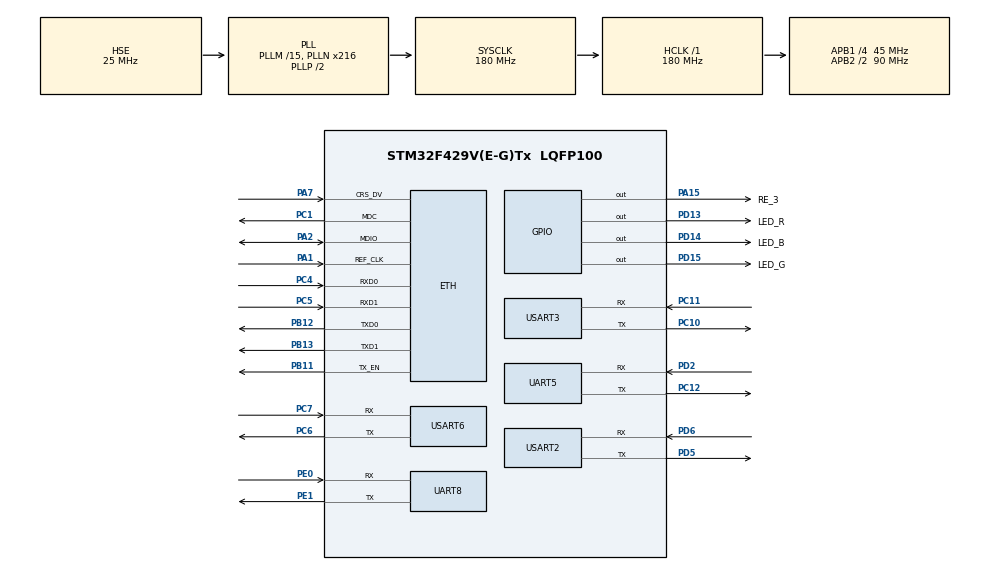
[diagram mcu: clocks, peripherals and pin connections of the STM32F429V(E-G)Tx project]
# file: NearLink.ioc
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ETH.MediaInterface=HAL_ETH_RMII_MODE
Mcu.Family=STM32F4
Mcu.Name=STM32F429V(E-G)Tx
Mcu.Package=LQFP100
NVIC.PriorityGroup=NVIC_PRIORITYGROUP_4
PA1.Mode=RMII
PA1.Signal=ETH_REF_CLK
PA13.Mode=Serial_Wire
PA13.Signal=SYS_JTMS-SWDIO
PA14.Mode=Serial_Wire
PA14.Signal=SYS_JTCK-SWCLK
PA15.GPIO_Label=RE_3
PA15.Signal=GPIO_Output
PA2.Mode=RMII
PA2.Signal=ETH_MDIO
PA7.Mode=RMII
PA7.Signal=ETH_CRS_DV
PB11.Mode=RMII
PB11.Signal=ETH_TX_EN
PB12.Mode=RMII
PB12.Signal=ETH_TXD0
PB13.Mode=RMII
PB13.Signal=ETH_TXD1
PC1.Mode=RMII
PC1.Signal=ETH_MDC
PC10.Mode=Asynchronous
PC10.Signal=USART3_TX
PC11.Mode=Asynchronous
PC11.Signal=USART3_RX
PC12.Mode=Asynchronous
PC12.Signal=UART5_TX
PC4.Mode=RMII
PC4.Signal=ETH_RXD0
PC5.Mode=RMII
PC5.Signal=ETH_RXD1
PC6.Mode=Asynchronous
PC6.Signal=USART6_TX
PC7.Mode=Asynchronous
PC7.Signal=USART6_RX
PD13.GPIO_Label=LED_R
PD13.PinState=GPIO_PIN_SET
PD13.Signal=GPIO_Output
PD14.GPIO_Label=LED_B
PD14.PinState=GPIO_PIN_SET
PD14.Signal=GPIO_Output
PD15.GPIO_Label=LED_G
PD15.PinState=GPIO_PIN_SET
PD15.Signal=GPIO_Output
PD2.Mode=Asynchronous
PD2.Signal=UART5_RX
PD5.Mode=Asynchronous
PD5.Signal=USART2_TX
PD6.Mode=Asynchronous
PD6.Signal=USART2_RX
PE0.Mode=Asynchronous
PE0.Signal=UART8_RX
PE1.Mode=Asynchronous
PE1.Signal=UART8_TX
PH0/OSC_IN.Mode=HSE-External-Oscillator
PH0/OSC_IN.Signal=RCC_OSC_IN
PH1/OSC_OUT.Mode=HSE-External-Oscillator
PH1/OSC_OUT.Signal=RCC_OSC_OUT
ProjectManager.HeapSize=0x200
ProjectManager.StackSize=0x400
ProjectManager.TargetToolchain=MDK-ARM V5.32
RCC.48MHZClocksFreq_Value=90000000
RCC.AHBFreq_Value=180000000
RCC.APB1CLKDivider=RCC_HCLK_DIV4
RCC.APB1Freq_Value=45000000
RCC.APB1TimFreq_Value=90000000
RCC.APB2CLKDivider=RCC_HCLK_DIV2
RCC.APB2Freq_Value=90000000
RCC.APB2TimFreq_Value=180000000
RCC.CortexFreq_Value=180000000
RCC.HCLKFreq_Value=180000000
RCC.HSE_VALUE=25000000
RCC.HSI_VALUE=16000000
RCC.LSE_VALUE=32768
RCC.PLLM=15
RCC.PLLN=216
RCC.PLLSourceVirtual=RCC_PLLSOURCE_HSE
RCC.SYSCLKFreq_VALUE=180000000
RCC.SYSCLKSource=RCC_SYSCLKSOURCE_PLLCLK
RCC.VCOOutputFreq_Value=360000000
UART5.VirtualMode=Asynchronous
UART8.VirtualMode=Asynchronous
USART2.VirtualMode=VM_ASYNC
USART3.VirtualMode=VM_ASYNC
USART6.VirtualMode=VM_ASYNC
board=custom

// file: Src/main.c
/* USER CODE BEGIN Header */
/**
  ******************************************************************************
  * @file           : main.c
  * @brief          : Main program body
  ******************************************************************************
  * @attention
  *
  * Copyright (c) 2024 STMicroelectronics.
  * All rights reserved.
  *
  * This software is licensed under terms that can be found in the LICENSE file
  * in the root directory of this software component.
  * If no LICENSE file comes with this software, it is provided AS-IS.
  *
  ******************************************************************************
  */
/* USER CODE END Header */
#include "main.h"
#include "string.h"

ETH_TxPacketConfig TxConfig;
ETH_DMADescTypeDef  DMARxDscrTab[ETH_RX_DESC_CNT]; /* Ethernet Rx DMA Descriptors */
ETH_DMADescTypeDef  DMATxDscrTab[ETH_TX_DESC_CNT]; /* Ethernet Tx DMA Descriptors */

ETH_HandleTypeDef heth;

UART_HandleTypeDef huart5;
UART_HandleTypeDef huart8;
UART_HandleTypeDef huart2;
UART_HandleTypeDef huart3;
UART_HandleTypeDef huart6;

void SystemClock_Config(void);
static void MX_GPIO_Init(void);
static void MX_ETH_Init(void);
static void MX_UART5_Init(void);
static void MX_UART8_Init(void);
static void MX_USART2_UART_Init(void);
static void MX_USART3_UART_Init(void);
static void MX_USART6_UART_Init(void);

int main(void)
{

  /* MCU Configuration--------------------------------------------------------*/

  /* Reset of all peripherals, Initializes the Flash interface and the Systick. */
  HAL_Init();

  /* Configure the system clock */
  SystemClock_Config();

  /* Initialize all configured peripherals */
  MX_GPIO_Init();
  MX_ETH_Init();
  MX_UART5_Init();
  MX_UART8_Init();
  MX_USART2_UART_Init();
  MX_USART3_UART_Init();
  MX_USART6_UART_Init();
  /* USER CODE BEGIN 2 */
  //LL_SYSTICK_EnableIT();
  /* USER CODE END 2 */

  /* Infinite loop */
  while (1)
  {

  }
}

void SystemClock_Config(void)
{
  RCC_OscInitTypeDef RCC_OscInitStruct = {0};
  RCC_ClkInitTypeDef RCC_ClkInitStruct = {0};

  /** Configure the main internal regulator output voltage
  */
  __HAL_RCC_PWR_CLK_ENABLE();
  __HAL_PWR_VOLTAGESCALING_CONFIG(PWR_REGULATOR_VOLTAGE_SCALE1);

  /** Initializes the RCC Oscillators according to the specified parameters
  * in the RCC_OscInitTypeDef structure.
  */
  RCC_OscInitStruct.OscillatorType = RCC_OSCILLATORTYPE_HSE;
  RCC_OscInitStruct.HSEState = RCC_HSE_ON;
  RCC_OscInitStruct.PLL.PLLState = RCC_PLL_ON;
  RCC_OscInitStruct.PLL.PLLSource = RCC_PLLSOURCE_HSE;
  RCC_OscInitStruct.PLL.PLLM = 15;
  RCC_OscInitStruct.PLL.PLLN = 216;
  RCC_OscInitStruct.PLL.PLLP = RCC_PLLP_DIV2;
  RCC_OscInitStruct.PLL.PLLQ = 4;
  if (HAL_RCC_OscConfig(&RCC_OscInitStruct) != HAL_OK)
  {
    Error_Handler();
  }

  /** Activate the Over-Drive mode
  */
  if (HAL_PWREx_EnableOverDrive() != HAL_OK)
  {
    Error_Handler();
  }

  /** Initializes the CPU, AHB and APB buses clocks
  */
  RCC_ClkInitStruct.ClockType = RCC_CLOCKTYPE_HCLK|RCC_CLOCKTYPE_SYSCLK
                              |RCC_CLOCKTYPE_PCLK1|RCC_CLOCKTYPE_PCLK2;
  RCC_ClkInitStruct.SYSCLKSource = RCC_SYSCLKSOURCE_PLLCLK;
  RCC_ClkInitStruct.AHBCLKDivider = RCC_SYSCLK_DIV1;
  RCC_ClkInitStruct.APB1CLKDivider = RCC_HCLK_DIV4;
  RCC_ClkInitStruct.APB2CLKDivider = RCC_HCLK_DIV2;

  if (HAL_RCC_ClockConfig(&RCC_ClkInitStruct, FLASH_LATENCY_5) != HAL_OK)
  {
    Error_Handler();
  }
}

static void MX_ETH_Init(void)
{

   static uint8_t MACAddr[6];

  heth.Instance = ETH;
  MACAddr[0] = 0x00;
  MACAddr[1] = 0x80;
  MACAddr[2] = 0xE1;
  MACAddr[3] = 0x00;
  MACAddr[4] = 0x00;
  MACAddr[5] = 0x00;
  heth.Init.MACAddr = &MACAddr[0];
  heth.Init.MediaInterface = HAL_ETH_RMII_MODE;
  heth.Init.TxDesc = DMATxDscrTab;
  heth.Init.RxDesc = DMARxDscrTab;
  heth.Init.RxBuffLen = 1524;

  if (HAL_ETH_Init(&heth) != HAL_OK)
  {
    Error_Handler();
  }

  memset(&TxConfig, 0 , sizeof(ETH_TxPacketConfig));
  TxConfig.Attributes = ETH_TX_PACKETS_FEATURES_CSUM | ETH_TX_PACKETS_FEATURES_CRCPAD;
  TxConfig.ChecksumCtrl = ETH_CHECKSUM_IPHDR_PAYLOAD_INSERT_PHDR_CALC;
  TxConfig.CRCPadCtrl = ETH_CRC_PAD_INSERT;

}

static void MX_UART5_Init(void)
{

  huart5.Instance = UART5;
  huart5.Init.BaudRate = 115200;
  huart5.Init.WordLength = UART_WORDLENGTH_8B;
  huart5.Init.StopBits = UART_STOPBITS_1;
  huart5.Init.Parity = UART_PARITY_NONE;
  huart5.Init.Mode = UART_MODE_TX_RX;
  huart5.Init.HwFlowCtl = UART_HWCONTROL_NONE;
  huart5.Init.OverSampling = UART_OVERSAMPLING_16;
  if (HAL_UART_Init(&huart5) != HAL_OK)
  {
    Error_Handler();
  }

}

static void MX_UART8_Init(void)
{

  huart8.Instance = UART8;
  huart8.Init.BaudRate = 115200;
  huart8.Init.WordLength = UART_WORDLENGTH_8B;
  huart8.Init.StopBits = UART_STOPBITS_1;
  huart8.Init.Parity = UART_PARITY_NONE;
  huart8.Init.Mode = UART_MODE_TX_RX;
  huart8.Init.HwFlowCtl = UART_HWCONTROL_NONE;
  huart8.Init.OverSampling = UART_OVERSAMPLING_16;
  if (HAL_UART_Init(&huart8) != HAL_OK)
  {
    Error_Handler();
  }

}

static void MX_USART2_UART_Init(void)
{

  huart2.Instance = USART2;
  huart2.Init.BaudRate = 115200;
  huart2.Init.WordLength = UART_WORDLENGTH_8B;
  huart2.Init.StopBits = UART_STOPBITS_1;
  huart2.Init.Parity = UART_PARITY_NONE;
  huart2.Init.Mode = UART_MODE_TX_RX;
  huart2.Init.HwFlowCtl = UART_HWCONTROL_NONE;
  huart2.Init.OverSampling = UART_OVERSAMPLING_16;
  if (HAL_UART_Init(&huart2) != HAL_OK)
  {
    Error_Handler();
  }

}

static void MX_USART3_UART_Init(void)
{

  huart3.Instance = USART3;
  huart3.Init.BaudRate = 115200;
  huart3.Init.WordLength = UART_WORDLENGTH_8B;
  huart3.Init.StopBits = UART_STOPBITS_1;
  huart3.Init.Parity = UART_PARITY_NONE;
  huart3.Init.Mode = UART_MODE_TX_RX;
  huart3.Init.HwFlowCtl = UART_HWCONTROL_NONE;
  huart3.Init.OverSampling = UART_OVERSAMPLING_16;
  if (HAL_UART_Init(&huart3) != HAL_OK)
  {
    Error_Handler();
  }

}

static void MX_USART6_UART_Init(void)
{

  huart6.Instance = USART6;
  huart6.Init.BaudRate = 115200;
  huart6.Init.WordLength = UART_WORDLENGTH_8B;
  huart6.Init.StopBits = UART_STOPBITS_1;
  huart6.Init.Parity = UART_PARITY_NONE;
  huart6.Init.Mode = UART_MODE_TX_RX;
  huart6.Init.HwFlowCtl = UART_HWCONTROL_NONE;
  huart6.Init.OverSampling = UART_OVERSAMPLING_16;
  if (HAL_UART_Init(&huart6) != HAL_OK)
  {
    Error_Handler();
  }

}

static void MX_GPIO_Init(void)
{
  GPIO_InitTypeDef GPIO_InitStruct = {0};

  /* GPIO Ports Clock Enable */
  __HAL_RCC_GPIOH_CLK_ENABLE();
  __HAL_RCC_GPIOC_CLK_ENABLE();
  __HAL_RCC_GPIOA_CLK_ENABLE();
  __HAL_RCC_GPIOB_CLK_ENABLE();
  __HAL_RCC_GPIOD_CLK_ENABLE();
  __HAL_RCC_GPIOE_CLK_ENABLE();

  /*Configure GPIO pin Output Level */
  HAL_GPIO_WritePin(GPIOD, LED_R_Pin|LED_B_Pin|LED_G_Pin, GPIO_PIN_SET);

  /*Configure GPIO pin Output Level */
  HAL_GPIO_WritePin(RE_3_GPIO_Port, RE_3_Pin, GPIO_PIN_RESET);

  /*Configure GPIO pins : LED_R_Pin LED_B_Pin LED_G_Pin */
  GPIO_InitStruct.Pin = LED_R_Pin|LED_B_Pin|LED_G_Pin;
  GPIO_InitStruct.Mode = GPIO_MODE_OUTPUT_PP;
  GPIO_InitStruct.Pull = GPIO_NOPULL;
  GPIO_InitStruct.Speed = GPIO_SPEED_FREQ_LOW;
  HAL_GPIO_Init(GPIOD, &GPIO_InitStruct);

  /*Configure GPIO pin : RE_3_Pin */
  GPIO_InitStruct.Pin = RE_3_Pin;
  GPIO_InitStruct.Mode = GPIO_MODE_OUTPUT_PP;
  GPIO_InitStruct.Pull = GPIO_NOPULL;
  GPIO_InitStruct.Speed = GPIO_SPEED_FREQ_LOW;
  HAL_GPIO_Init(RE_3_GPIO_Port, &GPIO_InitStruct);

}

void Error_Handler(void)
{
  __disable_irq();
  while (1)
  {
  }
}
